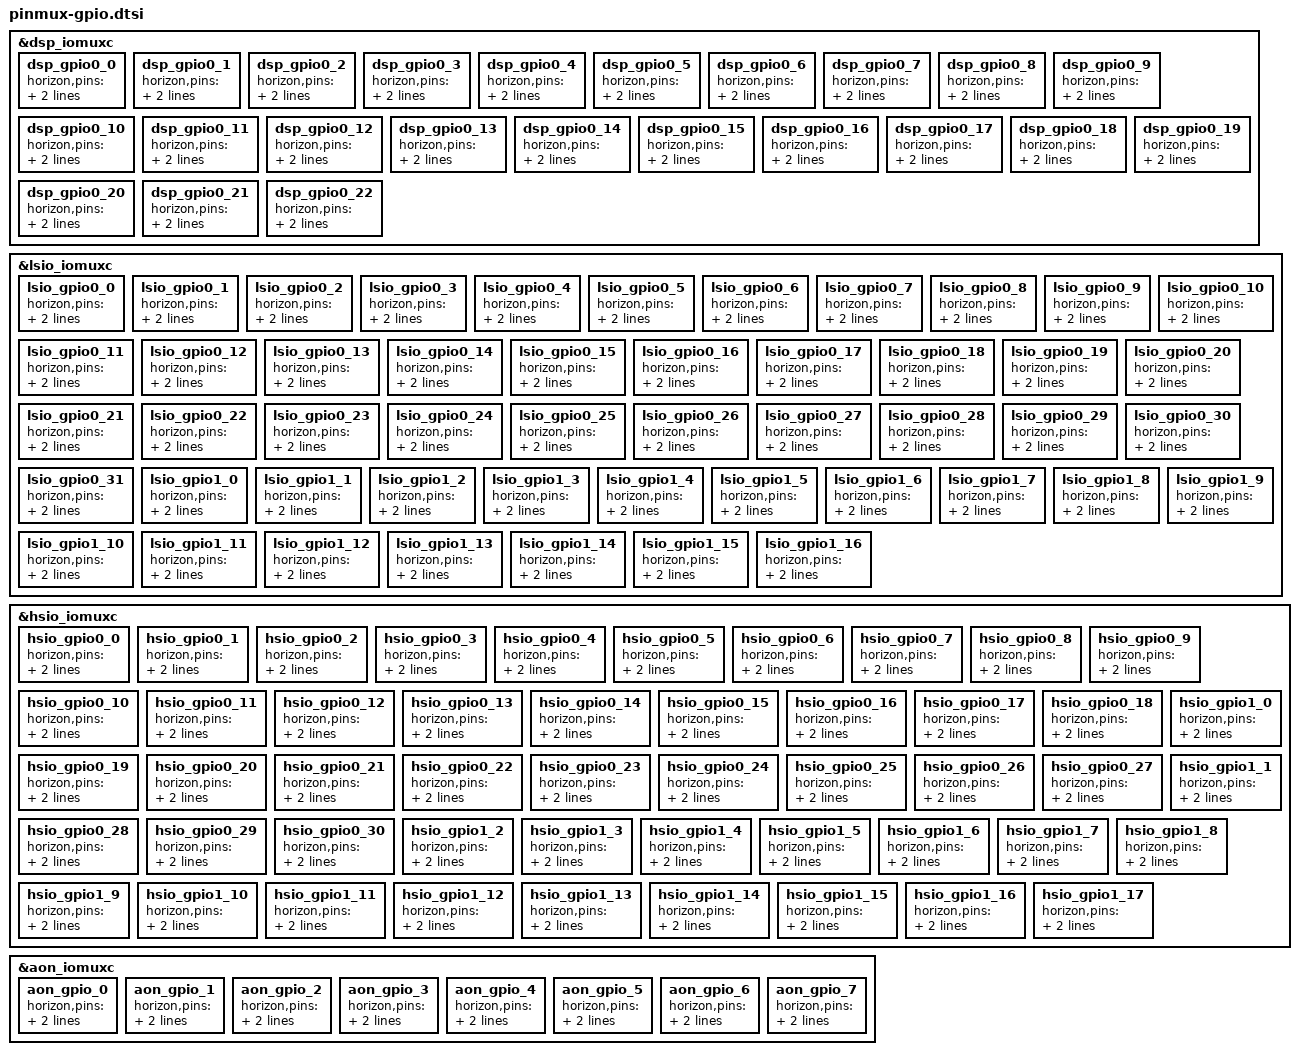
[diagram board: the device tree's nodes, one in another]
// SPDX-License-Identifier: GPL-2.0
/*
 * dtsi for pinctrl regarding gpio of Sunrise5 board
 *
 * Copyright(C) 2024, D-Robotics Co., Ltd. All rights reserved
 *
 */

 #include <dt-bindings/pinctrl/horizon-pinfunc.h>
 #include <dt-bindings/pinctrl/horizon-lsio-pinfunc.h>
 #include <dt-bindings/pinctrl/horizon-hsio-pinfunc.h>
 #include <dt-bindings/pinctrl/horizon-disp-pinfunc.h>
 #include <dt-bindings/pinctrl/horizon-aon-pinfunc.h>
 /*
  * The horizon,pins defined in each group is a tuple of
  * <pin_id, mux_reg_offset, mux_reg_bit, mux mode, pinconf_attributes>
  * attributes include pull up/down and drive strength, etc.
  */

&dsp_iomuxc {
	dsp_gpio0_0: dsp_gpio0_0 {
		horizon,pins = <
			DSP_I2C7_SCL  DSP_PINMUX_0  BIT_OFFSET2  MUX_ALT1  &pconf_input_en_1v8
		>;
	};
	dsp_gpio0_1: dsp_gpio0_1 {
		horizon,pins = <
			DSP_I2C7_SDA  DSP_PINMUX_0  BIT_OFFSET0  MUX_ALT1  &pconf_input_en_1v8
		>;
	};

	dsp_gpio0_2: dsp_gpio0_2 {
		horizon,pins = <
			DSP_UART0_RXD  DSP_PINMUX_1  BIT_OFFSET10  MUX_ALT1  &pconf_input_en_1v8
		>;
	};

	dsp_gpio0_3: dsp_gpio0_3 {
		horizon,pins = <
			DSP_UART0_TXD  DSP_PINMUX_1  BIT_OFFSET12  MUX_ALT1  &pconf_input_en_1v8
		>;
	};

	dsp_gpio0_4: dsp_gpio0_4 {
		horizon,pins = <
			DSP_I2S0_MCLK  DSP_PINMUX_0  BIT_OFFSET8  MUX_ALT1  &pconf_input_en_1v8
		>;
	};

	dsp_gpio0_5: dsp_gpio0_5 {
		horizon,pins = <
			DSP_I2S0_SCLK  DSP_PINMUX_0  BIT_OFFSET10  MUX_ALT1  &pconf_input_en_1v8
		>;
	};

	dsp_gpio0_6: dsp_gpio0_6 {
		horizon,pins = <
			DSP_I2S0_WS  DSP_PINMUX_0  BIT_OFFSET12  MUX_ALT1  &pconf_input_en_1v8
		>;
	};

	dsp_gpio0_7: dsp_gpio0_7 {
		horizon,pins = <
			DSP_I2S0_DI  DSP_PINMUX_0  BIT_OFFSET4  MUX_ALT1  &pconf_input_en_1v8
		>;
	};

	dsp_gpio0_8: dsp_gpio0_8 {
		horizon,pins = <
			DSP_I2S0_DO  DSP_PINMUX_0  BIT_OFFSET6  MUX_ALT1  &pconf_input_en_1v8
		>;
	};

	dsp_gpio0_9: dsp_gpio0_9 {
		horizon,pins = <
			DSP_I2S1_MCLK  DSP_PINMUX_0  BIT_OFFSET18  MUX_ALT1  &pconf_input_en_3v3
		>;
	};

	dsp_gpio0_10: dsp_gpio0_10 {
		horizon,pins = <
			DSP_I2S1_SCLK  DSP_PINMUX_0  BIT_OFFSET20  MUX_ALT1  &pconf_input_en_3v3
		>;
	};

	dsp_gpio0_11: dsp_gpio0_11 {
		horizon,pins = <
			DSP_I2S1_WS  DSP_PINMUX_0  BIT_OFFSET22  MUX_ALT1  &pconf_input_en_3v3
		>;
	};

	dsp_gpio0_12: dsp_gpio0_12 {
		horizon,pins = <
			DSP_I2S1_DI  DSP_PINMUX_0  BIT_OFFSET14  MUX_ALT1  &pconf_input_en_3v3
		>;
	};

	dsp_gpio0_13: dsp_gpio0_13 {
		horizon,pins = <
			DSP_I2S1_DO  DSP_PINMUX_0  BIT_OFFSET16  MUX_ALT1  &pconf_input_en_3v3
		>;
	};

	dsp_gpio0_14: dsp_gpio0_14 {
		horizon,pins = <
			DSP_PDM_CKO  DSP_PINMUX_0  BIT_OFFSET24  MUX_ALT1  &pconf_input_en_1v8
		>;
	};

	dsp_gpio0_15: dsp_gpio0_15 {
		horizon,pins = <
			DSP_PDM_IN0  DSP_PINMUX_0  BIT_OFFSET26  MUX_ALT1  &pconf_input_en_1v8
		>;
	};

	dsp_gpio0_16: dsp_gpio0_16 {
		horizon,pins = <
			DSP_PDM_IN1  DSP_PINMUX_0  BIT_OFFSET28  MUX_ALT1  &pconf_input_en_1v8
		>;
	};

	dsp_gpio0_17: dsp_gpio0_17 {
		horizon,pins = <
			DSP_PDM_IN2  DSP_PINMUX_0  BIT_OFFSET30  MUX_ALT1  &pconf_input_en_1v8
		>;
	};

	dsp_gpio0_18: dsp_gpio0_18 {
		horizon,pins = <
			DSP_PDM_IN3  DSP_PINMUX_1  BIT_OFFSET0  MUX_ALT1  &pconf_input_en_1v8
		>;
	};

	dsp_gpio0_19: dsp_gpio0_19 {
		horizon,pins = <
			DSP_SPI6_SCLK  DSP_PINMUX_1  BIT_OFFSET6  MUX_ALT1  &pconf_input_en_1v8
		>;
	};

	dsp_gpio0_20: dsp_gpio0_20 {
		horizon,pins = <
			DSP_SPI6_SSN  DSP_PINMUX_1  BIT_OFFSET8  MUX_ALT1  &pconf_input_en_1v8
		>;
	};

	dsp_gpio0_21: dsp_gpio0_21 {
		horizon,pins = <
			DSP_SPI6_MISO  DSP_PINMUX_1  BIT_OFFSET2  MUX_ALT1  &pconf_input_en_1v8
		>;
	};

	dsp_gpio0_22: dsp_gpio0_22 {
		horizon,pins = <
			DSP_SPI6_MOSI  DSP_PINMUX_1  BIT_OFFSET4  MUX_ALT1  &pconf_input_en_1v8
		>;
	};
};

  &lsio_iomuxc {

	/* LSIO_GPIO0 0-31 */
	lsio_gpio0_0: lsio_gpio0_0 {
		horizon,pins = <
			LSIO_UART7_RX	LSIO_PINMUX_3 BIT_OFFSET4	MUX_ALT2	&pconf_input_en_3v3
		>;
	};

	lsio_gpio0_1: lsio_gpio0_1 {
		horizon,pins = <
			LSIO_UART7_TX	LSIO_PINMUX_3 BIT_OFFSET6	MUX_ALT2	&pconf_input_en_3v3
		>;
	};

	lsio_gpio0_2: lsio_gpio0_2 {
		horizon,pins = <
			LSIO_UART7_CTS	LSIO_PINMUX_3 BIT_OFFSET8	MUX_ALT2	&pconf_input_en_3v3
		>;
	};

	lsio_gpio0_3: lsio_gpio0_3 {
		horizon,pins = <
			LSIO_UART7_RTS	LSIO_PINMUX_3 BIT_OFFSET10	MUX_ALT2	&pconf_input_en_3v3
		>;
	};

	lsio_gpio0_4: lsio_gpio0_4 {
		horizon,pins = <
			LSIO_UART1_RX	LSIO_PINMUX_3 BIT_OFFSET12	MUX_ALT2	&pconf_input_en_3v3
		>;
	};

	lsio_gpio0_5: lsio_gpio0_5 {
		horizon,pins = <
			LSIO_UART1_TX	LSIO_PINMUX_3 BIT_OFFSET14	MUX_ALT2	&pconf_input_en_3v3
		>;
	};

	lsio_gpio0_6: lsio_gpio0_6 {
		horizon,pins = <
			LSIO_UART1_CTS	LSIO_PINMUX_3 BIT_OFFSET28	MUX_ALT2	&pconf_input_en_3v3
		>;
	};

	lsio_gpio0_7: lsio_gpio0_7 {
		horizon,pins = <
			LSIO_UART1_RTS	LSIO_PINMUX_3 BIT_OFFSET30	MUX_ALT2	&pconf_input_en_3v3
		>;
	};

	lsio_gpio0_8: lsio_gpio0_8 {
		horizon,pins = <
			LSIO_UART2_RX	LSIO_PINMUX_3 BIT_OFFSET16	MUX_ALT2	&pconf_input_en_3v3
		>;
	};

	lsio_gpio0_9: lsio_gpio0_9 {
		horizon,pins = <
			LSIO_UART2_TX	LSIO_PINMUX_3 BIT_OFFSET18	MUX_ALT2	&pconf_input_en_3v3
		>;
	};

	lsio_gpio0_10: lsio_gpio0_10 {
		horizon,pins = <
			LSIO_UART3_RX	LSIO_PINMUX_3 BIT_OFFSET20	MUX_ALT2	&pconf_input_en_3v3
		>;
	};

	lsio_gpio0_11: lsio_gpio0_11 {
		horizon,pins = <
			LSIO_UART3_TX	LSIO_PINMUX_3 BIT_OFFSET22	MUX_ALT2	&pconf_input_en_3v3
		>;
	};

	lsio_gpio0_12: lsio_gpio0_12 {
		horizon,pins = <
			LSIO_UART4_RX	LSIO_PINMUX_3 BIT_OFFSET24	MUX_ALT2	&pconf_input_en_3v3
		>;
	};

	lsio_gpio0_13: lsio_gpio0_13 {
		horizon,pins = <
			LSIO_UART4_TX	LSIO_PINMUX_3 BIT_OFFSET26	MUX_ALT2	&pconf_input_en_3v3
		>;
	};

	lsio_gpio0_14: lsio_gpio0_14 {
		horizon,pins = <
			LSIO_SPI0_SCLK	LSIO_PINMUX_1 BIT_OFFSET0	MUX_ALT2	&pconf_input_en_1v8
		>;
	};

	lsio_gpio0_15: lsio_gpio0_15 {
		horizon,pins = <
			LSIO_SPI1_SSN_1	LSIO_PINMUX_0 BIT_OFFSET0	MUX_ALT1	&pconf_input_en_1v8
		>;
	};

	lsio_gpio0_16: lsio_gpio0_16 {
		horizon,pins = <
			LSIO_SPI1_SCLK	LSIO_PINMUX_0 BIT_OFFSET2	MUX_ALT1	&pconf_input_en_1v8
		>;
	};

	lsio_gpio0_17: lsio_gpio0_17 {
		horizon,pins = <
			LSIO_SPI1_SSN	LSIO_PINMUX_0 BIT_OFFSET4	MUX_ALT1	&pconf_input_en_1v8
		>;
	};

	lsio_gpio0_18: lsio_gpio0_18 {
		horizon,pins = <
			LSIO_SPI1_MISO	LSIO_PINMUX_0 BIT_OFFSET6	MUX_ALT1	&pconf_input_en_1v8
		>;
	};

	lsio_gpio0_19: lsio_gpio0_19 {
		horizon,pins = <
			LSIO_SPI1_MOSI	LSIO_PINMUX_0 BIT_OFFSET8	MUX_ALT1	&pconf_input_en_1v8
		>;
	};

	lsio_gpio0_20: lsio_gpio0_20 {
		horizon,pins = <
			LSIO_SPI2_SCLK	LSIO_PINMUX_1 BIT_OFFSET16	MUX_ALT1	&pconf_input_en_3v3
		>;
	};

	lsio_gpio0_21: lsio_gpio0_21 {
		horizon,pins = <
			LSIO_SPI2_SSN	LSIO_PINMUX_1 BIT_OFFSET18	MUX_ALT1	&pconf_input_en_3v3
		>;
	};

	lsio_gpio0_22: lsio_gpio0_22 {
		horizon,pins = <
			LSIO_SPI2_MISO	LSIO_PINMUX_1 BIT_OFFSET20	MUX_ALT1	&pconf_input_en_3v3
		>;
	};

	lsio_gpio0_23: lsio_gpio0_23 {
		horizon,pins = <
			LSIO_SPI2_MOSI	LSIO_PINMUX_1 BIT_OFFSET22	MUX_ALT1	&pconf_input_en_3v3
		>;
	};

	lsio_gpio0_24: lsio_gpio0_24 {
		horizon,pins = <
			LSIO_SPI3_SCLK	LSIO_PINMUX_1 BIT_OFFSET24	MUX_ALT1	&pconf_input_en_1v8
		>;
	};

	lsio_gpio0_25: lsio_gpio0_25 {
		horizon,pins = <
			LSIO_SPI3_SSN	LSIO_PINMUX_1 BIT_OFFSET26	MUX_ALT1	&pconf_input_en_1v8
		>;
	};

	lsio_gpio0_26: lsio_gpio0_26 {
		horizon,pins = <
			LSIO_SPI3_MISO	LSIO_PINMUX_1 BIT_OFFSET28	MUX_ALT1	&pconf_input_en_1v8
		>;
	};

	lsio_gpio0_27: lsio_gpio0_27 {
		horizon,pins = <
			LSIO_SPI3_MOSI	LSIO_PINMUX_1 BIT_OFFSET30	MUX_ALT1	&pconf_input_en_1v8
		>;
	};

	lsio_gpio0_28: lsio_gpio0_28 {
		horizon,pins = <
			LSIO_SPI4_SCLK	LSIO_PINMUX_2	BIT_OFFSET0	MUX_ALT1	&pconf_input_en_1v8
		>;
	};

	lsio_gpio0_29: lsio_gpio0_29 {
		horizon,pins = <
			LSIO_SPI4_SSN	LSIO_PINMUX_2	BIT_OFFSET2	MUX_ALT1	&pconf_output_normal
		>;
	};

	lsio_gpio0_30: lsio_gpio0_30 {
		horizon,pins = <
			LSIO_SPI4_MISO	LSIO_PINMUX_2	BIT_OFFSET4	MUX_ALT1	&pconf_input_en_1v8
		>;
	};

	lsio_gpio0_31: lsio_gpio0_31 {
		horizon,pins = <
			LSIO_SPI4_MOSI	LSIO_PINMUX_2	BIT_OFFSET6	MUX_ALT1	&pconf_input_en_1v8
		>;
	};

	/* LSIO_GPIO1 0-16 */
	lsio_gpio1_0: lsio_gpio1_0 {
		horizon,pins = <
			LSIO_SPI5_SCLK	LSIO_PINMUX_2	BIT_OFFSET8		MUX_ALT1	&pconf_input_en_1v8
		>;
	};

	lsio_gpio1_1: lsio_gpio1_1 {
		horizon,pins = <
			LSIO_SPI5_SSN	LSIO_PINMUX_2	BIT_OFFSET10	MUX_ALT1	&pconf_input_en_1v8
		>;
	};

	lsio_gpio1_2: lsio_gpio1_2 {
		horizon,pins = <
			LSIO_SPI5_MISO	LSIO_PINMUX_2	BIT_OFFSET12	MUX_ALT1	&pconf_input_en_1v8
		>;
	};

	lsio_gpio1_3: lsio_gpio1_3 {
		horizon,pins = <
			LSIO_SPI5_MOSI	LSIO_PINMUX_2	BIT_OFFSET14	MUX_ALT1	&pconf_input_en_1v8
		>;
	};

	lsio_gpio1_4: lsio_gpio1_4 {
		horizon,pins = <
			LSIO_SPI0_SSN	LSIO_PINMUX_1	BIT_OFFSET2	MUX_ALT2	&pconf_input_en_1v8
		>;
	};

	lsio_gpio1_5: lsio_gpio1_5 {
		horizon,pins = <
			LSIO_SPI0_MISO	LSIO_PINMUX_1	BIT_OFFSET4	MUX_ALT2	&pconf_input_en_1v8
		>;
	};

	lsio_gpio1_6: lsio_gpio1_6 {
		horizon,pins = <
			LSIO_SPI0_MOSI	LSIO_PINMUX_1	BIT_OFFSET6	MUX_ALT2	&pconf_input_en_1v8
		>;
	};

	lsio_gpio1_7: lsio_gpio1_7 {
		horizon,pins = <
			LSIO_I2C0_SCL	LSIO_PINMUX_2	BIT_OFFSET16	MUX_ALT1	&pconf_input_en_3v3
		>;
	};

	lsio_gpio1_8: lsio_gpio1_8 {
		horizon,pins = <
			LSIO_I2C0_SDA	LSIO_PINMUX_2	BIT_OFFSET18	MUX_ALT1	&pconf_input_en_3v3
		>;
	};

	lsio_gpio1_9: lsio_gpio1_9 {
		horizon,pins = <
			LSIO_I2C1_SCL	LSIO_PINMUX_2	BIT_OFFSET20	MUX_ALT1	&pconf_input_en_3v3
		>;
	};

	lsio_gpio1_10: lsio_gpio1_10 {
		horizon,pins = <
			LSIO_I2C1_SDA	LSIO_PINMUX_2	BIT_OFFSET22	MUX_ALT1	&pconf_input_en_3v3
		>;
	};

	lsio_gpio1_11: lsio_gpio1_11 {
		horizon,pins = <
			LSIO_I2C2_SCL	LSIO_PINMUX_2	BIT_OFFSET24	MUX_ALT1	&pconf_input_en_1v8
		>;
	};

	lsio_gpio1_12: lsio_gpio1_12 {
		horizon,pins = <
			LSIO_I2C2_SDA	LSIO_PINMUX_2	BIT_OFFSET26	MUX_ALT1	&pconf_input_en_1v8
		>;
	};

	lsio_gpio1_13: lsio_gpio1_13 {
		horizon,pins = <
			LSIO_I2C3_SCL	LSIO_PINMUX_2	BIT_OFFSET28	MUX_ALT1	&pconf_input_en_1v8
		>;
	};

	lsio_gpio1_14: lsio_gpio1_14 {
		horizon,pins = <
			LSIO_I2C3_SDA	LSIO_PINMUX_2	BIT_OFFSET30	MUX_ALT1	&pconf_input_en_1v8
		>;
	};

	lsio_gpio1_15: lsio_gpio1_15 {
		horizon,pins = <
			LSIO_I2C4_SCL	LSIO_PINMUX_3	BIT_OFFSET0	MUX_ALT1	&pconf_input_en_1v8
		>;
	};

	lsio_gpio1_16: lsio_gpio1_16 {
		horizon,pins = <
			LSIO_I2C4_SDA	LSIO_PINMUX_3	BIT_OFFSET2	MUX_ALT1	&pconf_input_en_1v8
		>;
	};
};

&hsio_iomuxc {

	/* HSIO_GPIO0 0-30 */
	hsio_gpio0_0: hsio_gpio0_0 {
		horizon,pins = <
			HSIO_ENET_MDC	HSIO_PINMUX_1	BIT_OFFSET30	MUX_ALT2	&pconf_input_en_1v8
		>;
	};

	hsio_gpio0_1: hsio_gpio0_1 {
		horizon,pins = <
			HSIO_ENET_MDIO		HSIO_PINMUX_1	BIT_OFFSET28	MUX_ALT2	&pconf_input_en_1v8
		>;
	};

	hsio_gpio0_2: hsio_gpio0_2 {
		horizon,pins = <
			HSIO_ENET_TXD_0		HSIO_PINMUX_1	BIT_OFFSET26	MUX_ALT2	&pconf_input_en_1v8
		>;
	};

	hsio_gpio0_3: hsio_gpio0_3 {
		horizon,pins = <
			HSIO_ENET_TXD_1		HSIO_PINMUX_1	BIT_OFFSET24	MUX_ALT2	&pconf_input_en_1v8
		>;
	};

	hsio_gpio0_4: hsio_gpio0_4 {
		horizon,pins = <
			HSIO_ENET_TXD_2		HSIO_PINMUX_1	BIT_OFFSET22	MUX_ALT2	&pconf_input_en_1v8
		>;
	};

	hsio_gpio0_5: hsio_gpio0_5 {
		horizon,pins = <
			HSIO_ENET_TXD_3		HSIO_PINMUX_1	BIT_OFFSET20	MUX_ALT2	&pconf_input_en_1v8
		>;
	};

	hsio_gpio0_6: hsio_gpio0_6 {
		horizon,pins = <
			HSIO_ENET_TXEN		HSIO_PINMUX_1	BIT_OFFSET18	MUX_ALT2	&pconf_input_en_1v8
		>;
	};

	hsio_gpio0_7: hsio_gpio0_7 {
		horizon,pins = <
			HSIO_ENET_TX_CLK	HSIO_PINMUX_1	BIT_OFFSET16	MUX_ALT2	&pconf_input_en_1v8
		>;
	};

	hsio_gpio0_8: hsio_gpio0_8 {
		horizon,pins = <
			HSIO_ENET_RX_CLK	HSIO_PINMUX_1	BIT_OFFSET14	MUX_ALT2	&pconf_input_en_1v8
		>;
	};

	hsio_gpio0_9: hsio_gpio0_9 {
		horizon,pins = <
			HSIO_ENET_RXD_0		HSIO_PINMUX_1	BIT_OFFSET12	MUX_ALT2	&pconf_input_en_1v8
		>;
	};

	hsio_gpio0_10: hsio_gpio0_10 {
		horizon,pins = <
			HSIO_ENET_RXD_1		HSIO_PINMUX_1	BIT_OFFSET10	MUX_ALT2	&pconf_input_en_1v8
		>;
	};

	hsio_gpio0_11: hsio_gpio0_11 {
		horizon,pins = <
			HSIO_ENET_RXD_2		HSIO_PINMUX_1	BIT_OFFSET8		MUX_ALT2	&pconf_input_en_1v8
		>;
	};

	hsio_gpio0_12: hsio_gpio0_12 {
		horizon,pins = <
			HSIO_ENET_RXD_3		HSIO_PINMUX_1	BIT_OFFSET6		MUX_ALT2	&pconf_input_en_1v8
		>;
	};

	hsio_gpio0_13: hsio_gpio0_13 {
		horizon,pins = <
			HSIO_ENET_RXDV		HSIO_PINMUX_1	BIT_OFFSET4		MUX_ALT2	&pconf_input_en_1v8
		>;
	};

	hsio_gpio0_14: hsio_gpio0_14 {
		horizon,pins = <
			HSIO_ENET_PHY_CLK	HSIO_PINMUX_1	BIT_OFFSET2		MUX_ALT2	&pconf_input_en_1v8
		>;
	};

	hsio_gpio0_15: hsio_gpio0_15 {
		horizon,pins = <
			HSIO_SD_WP		HSIO_PINMUX_2	BIT_OFFSET24	MUX_ALT2	&pconf_input_en_3v3
		>;
	};

	hsio_gpio0_16: hsio_gpio0_16 {
		horizon,pins = <
			HSIO_SD_CLK		HSIO_PINMUX_2	BIT_OFFSET22	MUX_ALT2	&pconf_input_en_3v3
		>;
	};

	hsio_gpio0_17: hsio_gpio0_17 {
		horizon,pins = <
			HSIO_SD_CMD		HSIO_PINMUX_2	BIT_OFFSET20	MUX_ALT2	&pconf_input_en_3v3
		>;
	};

	hsio_gpio0_18: hsio_gpio0_18 {
		horizon,pins = <
			HSIO_SD_CDN		HSIO_PINMUX_2	BIT_OFFSET18	MUX_ALT2	&pconf_input_en_3v3
		>;
	};

	hsio_gpio0_19: hsio_gpio0_19 {
		horizon,pins = <
			HSIO_SD_DATA0	HSIO_PINMUX_2	BIT_OFFSET16	MUX_ALT2	&pconf_input_en_3v3
		>;
	};

	hsio_gpio0_20: hsio_gpio0_20 {
		horizon,pins = <
			HSIO_SD_DATA1	HSIO_PINMUX_2	BIT_OFFSET14	MUX_ALT2	&pconf_input_en_3v3
		>;
	};

	hsio_gpio0_21: hsio_gpio0_21 {
		horizon,pins = <
			HSIO_SD_DATA2	HSIO_PINMUX_2	BIT_OFFSET12	MUX_ALT2	&pconf_input_en_3v3
		>;
	};

	hsio_gpio0_22: hsio_gpio0_22 {
		horizon,pins = <
			HSIO_SD_DATA3	HSIO_PINMUX_2	BIT_OFFSET10	MUX_ALT2	&pconf_input_en_3v3
		>;
	};

	hsio_gpio0_23: hsio_gpio0_23 {
		horizon,pins = <
			HSIO_SDIO_WP	HSIO_PINMUX_2	BIT_OFFSET8		MUX_ALT2	&pconf_input_en_1v8
		>;
	};

	hsio_gpio0_24: hsio_gpio0_24 {
		horizon,pins = <
			HSIO_SDIO_CLK	HSIO_PINMUX_0	BIT_OFFSET30	MUX_ALT2	&pconf_input_en_1v8
		>;
	};

	hsio_gpio0_25: hsio_gpio0_25 {
		horizon,pins = <
			HSIO_SDIO_CMD	HSIO_PINMUX_0	BIT_OFFSET28	MUX_ALT2	&pconf_input_en_1v8
		>;
	};

	hsio_gpio0_26: hsio_gpio0_26 {
		horizon,pins = <
			HSIO_SDIO_CDN	HSIO_PINMUX_0	BIT_OFFSET26	MUX_ALT2	&pconf_input_en_1v8
		>;
	};

	hsio_gpio0_27: hsio_gpio0_27 {
		horizon,pins = <
			HSIO_SDIO_DATA0	HSIO_PINMUX_1	BIT_OFFSET0		MUX_ALT2	&pconf_input_en_1v8
		>;
	};

	hsio_gpio0_28: hsio_gpio0_28 {
		horizon,pins = <
			HSIO_SDIO_DATA1	HSIO_PINMUX_2	BIT_OFFSET30	MUX_ALT2	&pconf_input_en_1v8
		>;
	};

	hsio_gpio0_29: hsio_gpio0_29 {
		horizon,pins = <
			HSIO_SDIO_DATA2	HSIO_PINMUX_2	BIT_OFFSET28	MUX_ALT2	&pconf_input_en_1v8
		>;
	};

	hsio_gpio0_30: hsio_gpio0_30 {
		horizon,pins = <
			HSIO_SDIO_DATA3	HSIO_PINMUX_2	BIT_OFFSET26	MUX_ALT2	&pconf_input_en_1v8
		>;
	};

	/* HSIO_GPIO1 0-17 */
	hsio_gpio1_0: hsio_gpio1_0 {
		horizon,pins = <
			HSIO_QSPI_SSN0		HSIO_PINMUX_0	BIT_OFFSET24	MUX_ALT2	&pconf_input_en_1v8
		>;
	};

	hsio_gpio1_1: hsio_gpio1_1 {
		horizon,pins = <
			HSIO_QSPI_SSN1		HSIO_PINMUX_0	BIT_OFFSET22	MUX_ALT2	&pconf_output_low
		>;
	};

	hsio_gpio1_2: hsio_gpio1_2 {
		horizon,pins = <
			HSIO_QSPI_SCLK		HSIO_PINMUX_0	BIT_OFFSET20	MUX_ALT2	&pconf_input_en_1v8
		>;
	};

	hsio_gpio1_3: hsio_gpio1_3 {
		horizon,pins = <
			HSIO_QSPI_DATA0		HSIO_PINMUX_2	BIT_OFFSET6	MUX_ALT2	&pconf_input_en_1v8
		>;
	};

	hsio_gpio1_4: hsio_gpio1_4 {
		horizon,pins = <
			HSIO_QSPI_DATA1		HSIO_PINMUX_2	BIT_OFFSET4	MUX_ALT2	&pconf_input_en_1v8
		>;
	};

	hsio_gpio1_5: hsio_gpio1_5 {
		horizon,pins = <
			HSIO_QSPI_DATA2		HSIO_PINMUX_2	BIT_OFFSET2	MUX_ALT2	&pconf_input_en_1v8
		>;
	};

	hsio_gpio1_6: hsio_gpio1_6 {
		horizon,pins = <
			HSIO_QSPI_DATA3		HSIO_PINMUX_2	BIT_OFFSET0	MUX_ALT2	&pconf_input_en_1v8
		>;
	};

	hsio_gpio1_7: hsio_gpio1_7 {
		horizon,pins = <
			HSIO_EMMC_CLK	HSIO_PINMUX_0	BIT_OFFSET18	MUX_ALT2	&pconf_input_en_1v8
		>;
	};

	hsio_gpio1_8: hsio_gpio1_8 {
		horizon,pins = <
			HSIO_EMMC_CMD	HSIO_PINMUX_0	BIT_OFFSET16	MUX_ALT2	&pconf_input_en_1v8
		>;
	};

	hsio_gpio1_9: hsio_gpio1_9 {
		horizon,pins = <
			HSIO_EMMC_DATA0	HSIO_PINMUX_0	BIT_OFFSET14	MUX_ALT2	&pconf_input_en_1v8
		>;
	};

	hsio_gpio1_10: hsio_gpio1_10 {
		horizon,pins = <
			HSIO_EMMC_DATA1	HSIO_PINMUX_0	BIT_OFFSET12	MUX_ALT2	&pconf_input_en_1v8
		>;
	};

	hsio_gpio1_11: hsio_gpio1_11 {
		horizon,pins = <
			HSIO_EMMC_DATA2	HSIO_PINMUX_0	BIT_OFFSET10	MUX_ALT2	&pconf_input_en_1v8
		>;
	};

	hsio_gpio1_12: hsio_gpio1_12 {
		horizon,pins = <
			HSIO_EMMC_DATA3	HSIO_PINMUX_0	BIT_OFFSET8		MUX_ALT2	&pconf_input_en_1v8
		>;
	};

	hsio_gpio1_13: hsio_gpio1_13 {
		horizon,pins = <
			HSIO_EMMC_DATA4	HSIO_PINMUX_0	BIT_OFFSET6		MUX_ALT2	&pconf_input_en_1v8
		>;
	};

	hsio_gpio1_14: hsio_gpio1_14 {
		horizon,pins = <
			HSIO_EMMC_DATA5	HSIO_PINMUX_0	BIT_OFFSET4		MUX_ALT2	&pconf_input_en_1v8
		>;
	};

	hsio_gpio1_15: hsio_gpio1_15 {
		horizon,pins = <
			HSIO_EMMC_DATA6	HSIO_PINMUX_0	BIT_OFFSET2		MUX_ALT2	&pconf_input_en_1v8
		>;
	};

	hsio_gpio1_16: hsio_gpio1_16 {
		horizon,pins = <
			HSIO_EMMC_DATA7	HSIO_PINMUX_0	BIT_OFFSET0		MUX_ALT2	&pconf_input_en_1v8
		>;
	};

	hsio_gpio1_17: hsio_gpio1_17 {
		horizon,pins = <
			HSIO_EMMC_RSTN	HSIO_PINMUX_3	BIT_OFFSET0		MUX_ALT2	&pconf_input_en_1v8
		>;
	};
};

&aon_iomuxc {
	/* AON_GPIO 0-7 */
	aon_gpio_0: aon_gpio_0 {
		horizon,pins = <
			AON_GPIO0_PIN0	INVALID_PINMUX	BIT_OFFSET0		MUX_ALT0	&pconf_input_en_1v8
		>;
	};

	aon_gpio_1: aon_gpio_1 {
		horizon,pins = <
			AON_GPIO0_PIN1	INVALID_PINMUX	BIT_OFFSET0		MUX_ALT0	&pconf_input_en_1v8
		>;
	};

	aon_gpio_2: aon_gpio_2 {
		horizon,pins = <
			AON_GPIO0_PIN2	INVALID_PINMUX	BIT_OFFSET0		MUX_ALT0	&pconf_input_en_1v8
		>;
	};

	aon_gpio_3: aon_gpio_3 {
		horizon,pins = <
			AON_GPIO0_PIN3	INVALID_PINMUX	BIT_OFFSET0		MUX_ALT0	&pconf_input_en_1v8
		>;
	};

	aon_gpio_4: aon_gpio_4 {
		horizon,pins = <
			AON_GPIO0_PIN4	INVALID_PINMUX	BIT_OFFSET0		MUX_ALT0	&pconf_input_en_1v8
		>;
	};

	aon_gpio_5: aon_gpio_5 {
		horizon,pins = <
			AON_ENV_VDD		AON_PINMUX_0	BIT_OFFSET8	MUX_ALT1	&pconf_input_en_1v8
		>;
	};
	aon_gpio_6: aon_gpio_6 {
		horizon,pins = <
			AON_ENV_CNN0	AON_PINMUX_0	BIT_OFFSET10	MUX_ALT1	&pconf_input_en_1v8
		>;
	};
	aon_gpio_7: aon_gpio_7 {
		horizon,pins = <
			AON_ENV_CNN1	AON_PINMUX_0	BIT_OFFSET12	MUX_ALT1	&pconf_input_en_1v8
		>;
	};
};
